# MKE15Z4 register map
Vendor: nxp.com; File version: 1.0
CPU: CM0PLUS r0p0, little endian, no MPU, no FPU, VTOR, 2 interrupt priority bits
Registers are 32-bit, read-write, reset 0x0 unless marked. A register's access mark holds for its fields unless they carry their own. Offsets are from the block's base; [hi:lo] are bit positions; {n}, {i} and the like mark numbered series; 'fields as' and 'values as' point back to an identical list.

## CRC — Cyclic Redundancy Check
Base 0x40032000; register names take the prefix CRC_
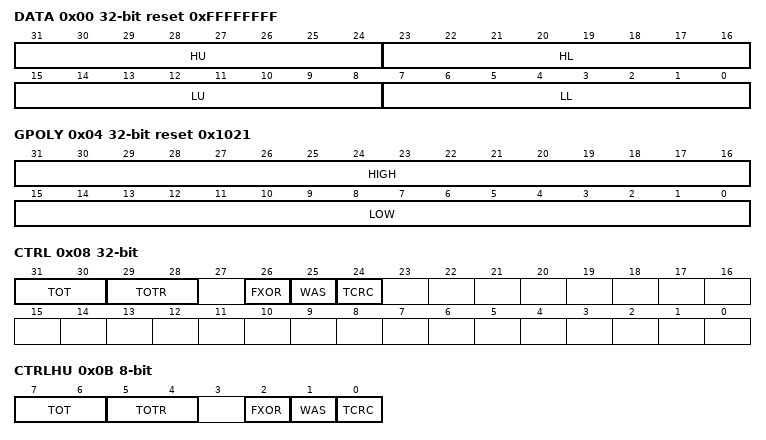
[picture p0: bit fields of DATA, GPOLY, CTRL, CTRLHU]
0x00 DATA reset 0xFFFFFFFF (DATA_DATAL_DATALL view) — CRC Data register
  [31:24] HU — CRC High Upper Byte
  [23:16] HL — CRC High Lower Byte
  [15:8] LU — CRC Low Upper Byte
  [7:0] LL — CRC Low Lower Byte
0x00 DATAL 16-bit reset 0xFFFF (DATA_DATAL_DATALL view) — CRC_DATAL register.
  [15:0] DATAL — DATAL stores the lower 16 bits of the 16/32 bit CRC
0x00 DATALL 8-bit reset 0xFF (DATA_DATAL_DATALL view) — CRC_DATALL register.
  [7:0] DATALL — CRCLL stores the first 8 bits of the 32 bit DATA
0x01 DATALU 8-bit reset 0xFF — CRC_DATALU register.
  [7:0] DATALU — DATALL stores the second 8 bits of the 32 bit CRC
0x02 DATAH 16-bit reset 0xFFFF (DATAH_DATAHL view) — CRC_DATAH register.
  [15:0] DATAH — DATAH stores the high 16 bits of the 16/32 bit CRC
0x02 DATAHL 8-bit reset 0xFF (DATAH_DATAHL view) — CRC_DATAHL register.
  [7:0] DATAHL — DATAHL stores the third 8 bits of the 32 bit CRC
0x03 DATAHU 8-bit reset 0xFF — CRC_DATAHU register.
  [7:0] DATAHU — DATAHU stores the fourth 8 bits of the 32 bit CRC
0x04 GPOLY reset 0x1021 (GPOLY_GPOLYL_GPOLYLL view) — CRC Polynomial register
  [31:16] HIGH — High Polynominal Half-word
  [15:0] LOW — Low Polynominal Half-word
0x04 GPOLYL 16-bit reset 0xFFFF (GPOLY_GPOLYL_GPOLYLL view) — CRC_GPOLYL register.
  [15:0] GPOLYL — POLYL stores the lower 16 bits of the 16/32 bit CRC polynomial value
0x04 GPOLYLL 8-bit reset 0xFF (GPOLY_GPOLYL_GPOLYLL view) — CRC_GPOLYLL register.
  [7:0] GPOLYLL — POLYLL stores the first 8 bits of the 32 bit CRC
0x05 GPOLYLU 8-bit reset 0xFF — CRC_GPOLYLU register.
  [7:0] GPOLYLU — POLYLL stores the second 8 bits of the 32 bit CRC
0x06 GPOLYH 16-bit reset 0xFFFF (GPOLYH_GPOLYHL view) — CRC_GPOLYH register.
  [15:0] GPOLYH — POLYH stores the high 16 bits of the 16/32 bit CRC polynomial value
0x06 GPOLYHL 8-bit reset 0xFF (GPOLYH_GPOLYHL view) — CRC_GPOLYHL register.
  [7:0] GPOLYHL — POLYHL stores the third 8 bits of the 32 bit CRC
0x07 GPOLYHU 8-bit reset 0xFF — CRC_GPOLYHU register.
  [7:0] GPOLYHU — POLYHU stores the fourth 8 bits of the 32 bit CRC
0x08 CTRL — CRC Control register
  [31:30] TOT — Type Of Transpose For Writes
    0=No transposition; 1=Bits in bytes are transposed; bytes are not transposed; 2=Both bits in bytes and bytes are transposed; 3=Only bytes are transposed; no bits in a byte are transposed
  [29:28] TOTR — Type Of Transpose For Read
    values as TOT
  [26] FXOR — Complement Read Of CRC Data Register
    0=No XOR on reading; 1=Invert or complement the read value of the CRC Data register
  [25] WAS — Write CRC Data Register As Seed
    0=Writes to the CRC data register are data values; 1=Writes to the CRC data register are seed values
  [24] TCRC — Width of CRC protocol.
    0=16-bit CRC protocol; 1=32-bit CRC protocol
0x0B CTRLHU 8-bit — CRC_CTRLHU register.
  [7:6] TOT
    0=No Transposition; 1=Bits in bytes are transposed, bytes are not transposed; 2=Both bits in bytes and bytes are transposed; 3=Only bytes are transposed; no bits in a byte are transposed
  [5:4] TOTR
    values as TOT
  [2] FXOR
    0=No XOR on reading; 1=Invert or complement the read value of CRC data register
  [1] WAS
    0=Writes to CRC data register are data values; 1=Writes to CRC data reguster are seed values
  [0] TCRC
    0=16-bit CRC protocol; 1=32-bit CRC protocol

## LPTMR0 — Low Power Timer
Base 0x40040000; register names take the prefix LPTMR0_
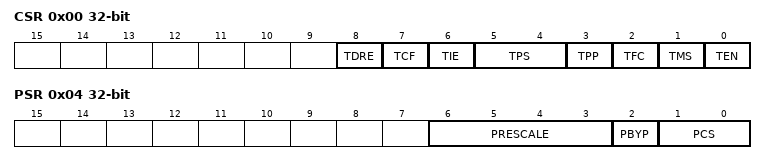
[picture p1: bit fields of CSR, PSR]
0x00 CSR — Low Power Timer Control Status Register
  [8] TDRE — Timer DMA Request Enable
    0=Timer DMA Request disabled; 1=Timer DMA Request enabled
  [7] TCF write-1-clears — Timer Compare Flag
    0=The value of CNR is not equal to CMR and increments; 1=The value of CNR is equal to CMR and increments
  [6] TIE — Timer Interrupt Enable
    0=Timer interrupt disabled; 1=Timer interrupt enabled
  [5:4] TPS — Timer Pin Select
    {v}=Pulse counter input {v} is selected (v=0..3)
  [3] TPP — Timer Pin Polarity
    0=Pulse Counter input source is active-high, and the CNR will increment on the rising-edge; 1=Pulse Counter input source is active-low, and the CNR will increment on the falling-edge
  [2] TFC — Timer Free-Running Counter
    0=CNR is reset whenever TCF is set; 1=CNR is reset on overflow
  [1] TMS — Timer Mode Select
    0=Time Counter mode; 1=Pulse Counter mode
  [0] TEN — Timer Enable
    0=LPTMR is disabled and internal logic is reset; 1=LPTMR is enabled
0x04 PSR — Low Power Timer Prescale Register
  [6:3] PRESCALE — Prescale Value
    0=Prescaler divides the prescaler clock by 2; glitch filter does not support this configuration; 1=Prescaler divides the prescaler clock by 4; glitch filter recognizes change on input pin after 2 rising clock edges; 2=Prescaler divides the prescaler clock by 8; glitch filter recognizes change on input pin after 4 rising clock edges; 3=Prescaler divides the prescaler clock by 16; glitch filter recognizes change on input pin after 8 rising clock edges; 4=Prescaler divides the prescaler clock by 32; glitch filter recognizes change on input pin after 16 rising clock edges; 5=Prescaler divides the prescaler clock by 64; glitch filter recognizes change on input pin after 32 rising clock edges; 6=Prescaler divides the prescaler clock by 128; glitch filter recognizes change on input pin after 64 rising clock edges; 7=Prescaler divides the prescaler clock by 256; glitch filter recognizes change on input pin after 128 rising clock edges; 8=Prescaler divides the prescaler clock by 512; glitch filter recognizes change on input pin after 256 rising clock edges; 9=Prescaler divides the prescaler clock by 1024; glitch filter recognizes change on input pin after 512 rising clock edges; 10=Prescaler divides the prescaler clock by 2048; glitch filter recognizes change on input pin after 1024 rising clock edges; 11=Prescaler divides the prescaler clock by 4096; glitch filter recognizes change on input pin after 2048 rising clock edges; 12=Prescaler divides the prescaler clock by 8192; glitch filter recognizes change on input pin after 4096 rising clock edges; 13=Prescaler divides the prescaler clock by 16,384; glitch filter recognizes change on input pin after 8192 rising clock edges; 14=Prescaler divides the prescaler clock by 32,768; glitch filter recognizes change on input pin after 16,384 rising clock edges; 15=Prescaler divides the prescaler clock by 65,536; glitch filter recognizes change on input pin after 32,768 rising clock edges
  [2] PBYP — Prescaler Bypass
    0=Prescaler/glitch filter is enabled; 1=Prescaler/glitch filter is bypassed
  [1:0] PCS — Prescaler Clock Select
    {v}=Prescaler/glitch filter clock {v} selected (v=0..3)
0x08 CMR — Low Power Timer Compare Register
  [15:0] COMPARE — Compare Value
0x0C CNR — Low Power Timer Counter Register
  [15:0] COUNTER — Counter Value

## Notices in the file
Copyright 2016-2020 NXP
All rights reserved.
SPDX-License-Identifier: BSD-3-Clause
